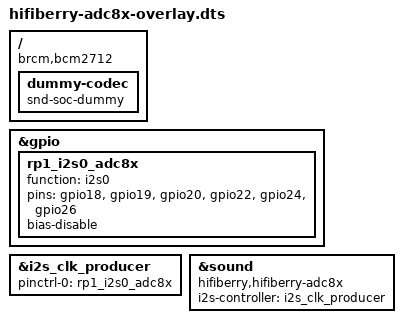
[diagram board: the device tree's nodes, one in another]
// Definitions for HiFiBerry ADC8x
/dts-v1/;
/plugin/;

/ {
	compatible = "brcm,bcm2712";

	fragment@0 {
		target = <&gpio>;
		__overlay__ {
			rp1_i2s0_adc8x: rp1_i2s0_adc8x {
				function = "i2s0";
				pins = "gpio18", "gpio19", "gpio20",
				       "gpio22", "gpio24", "gpio26";
				bias-disable;
				status = "okay";
			};
		};
	};

	fragment@1 {
		target = <&i2s_clk_producer>;
		__overlay__ {
			pinctrl-names = "default";
			pinctrl-0 = <&rp1_i2s0_adc8x>;
			status = "okay";
		};
	};

	fragment@2 {
		target-path = "/";
		__overlay__ {
			dummy-codec {
				#sound-dai-cells = <0>;
				compatible = "snd-soc-dummy";
				status = "okay";
			};
		};
	};

	fragment@3 {
		target = <&sound>;
		__overlay__ {
			compatible = "hifiberry,hifiberry-adc8x";
			i2s-controller = <&i2s_clk_producer>;
			status = "okay";
		};
	};

};
